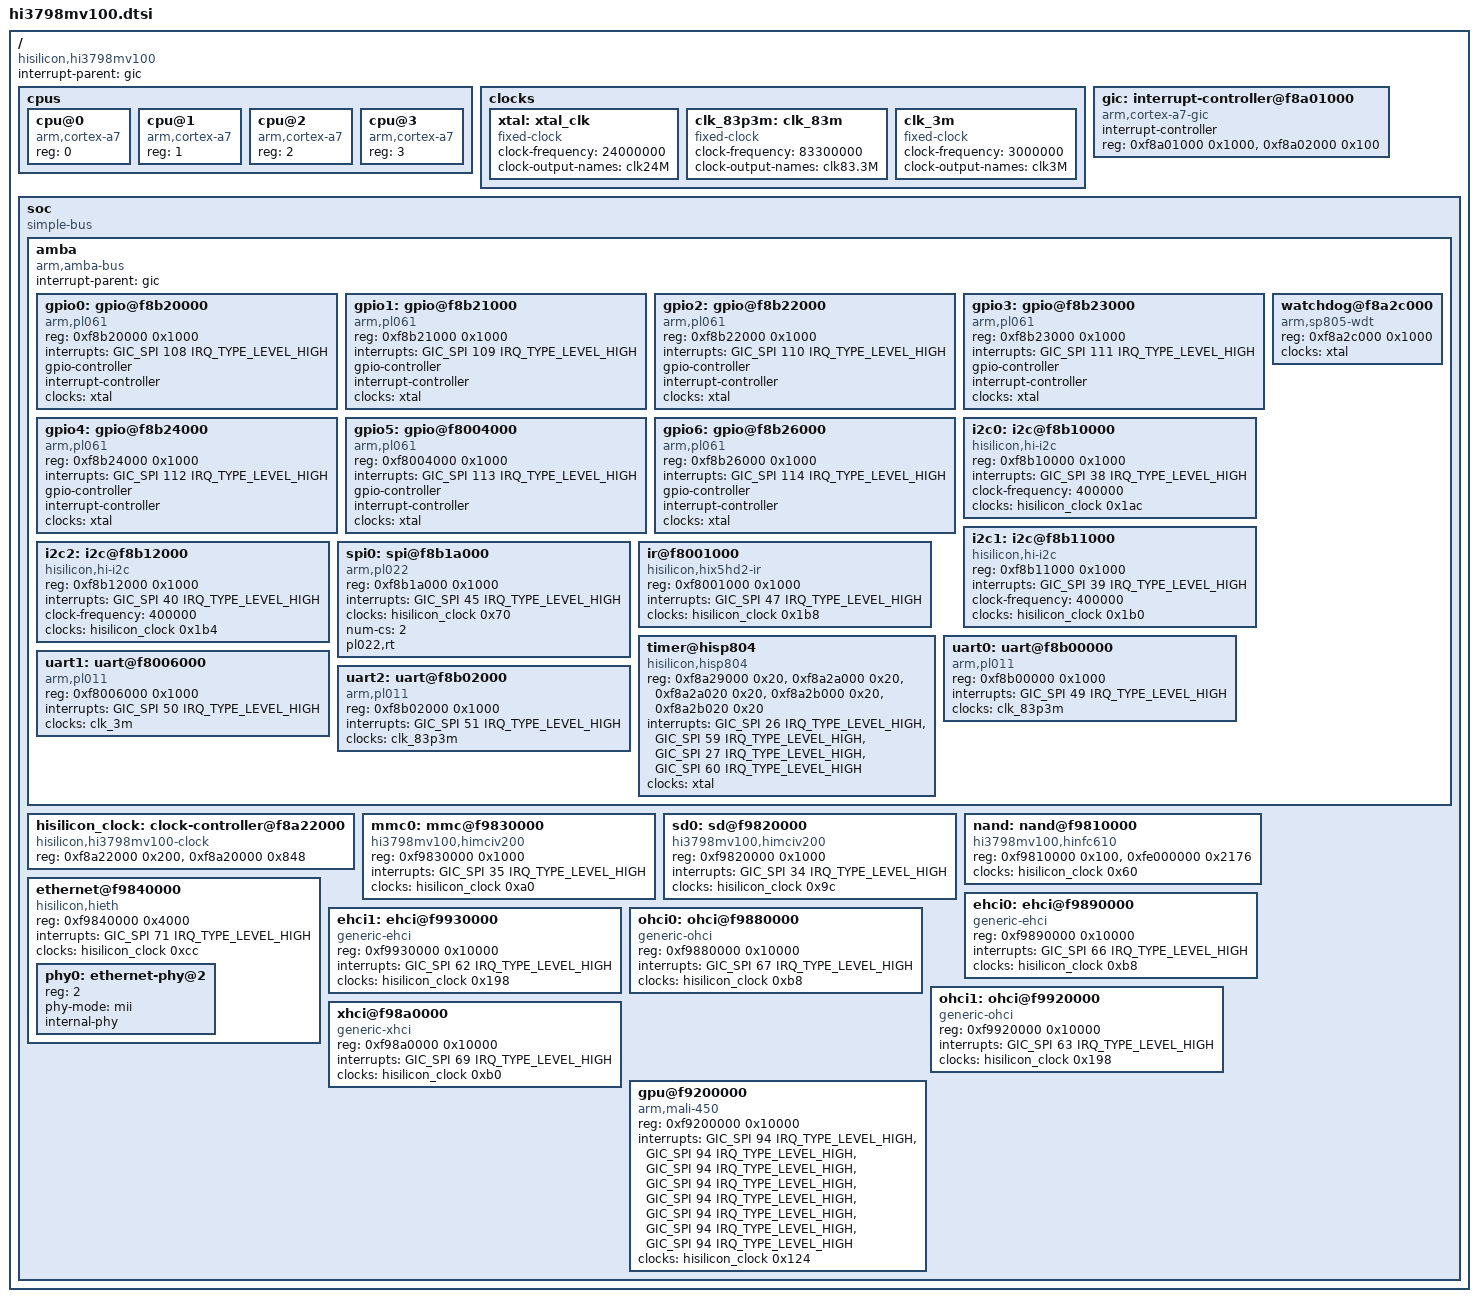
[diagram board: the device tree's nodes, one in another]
// SPDX-License-Identifier: GPL-2.0
/*
 * Device Tree Include for HiSilicon Hi3798MV100 SoC
 * Merged and cleaned from vendor dump + mainline-style structure
 */

#include <dt-bindings/interrupt-controller/arm-gic.h>
#include <dt-bindings/interrupt-controller/irq.h>

/ {
	compatible = "hisilicon,hi3798mv100";
	#address-cells = <1>;
	#size-cells = <1>;
	interrupt-parent = <&gic>;

	cpus {
		#address-cells = <1>;
		#size-cells = <0>;

		cpu@0 {
			device_type = "cpu";
			compatible = "arm,cortex-a7";
			reg = <0>;
		};
		cpu@1 {
			device_type = "cpu";
			compatible = "arm,cortex-a7";
			reg = <1>;
		};
		cpu@2 {
			device_type = "cpu";
			compatible = "arm,cortex-a7";
			reg = <2>;
		};
		cpu@3 {
			device_type = "cpu";
			compatible = "arm,cortex-a7";
			reg = <3>;
		};
	};

	clocks {
		xtal: xtal_clk {
			compatible = "fixed-clock";
			#clock-cells = <0>;
			clock-frequency = <24000000>;
			clock-output-names = "clk24M";
		};

		clk_83p3m: clk_83m {
			compatible = "fixed-clock";
			#clock-cells = <0>;
			clock-frequency = <83300000>;
			clock-output-names = "clk83.3M";
		};

		clk_3m: clk_3m {
			compatible = "fixed-clock";
			#clock-cells = <0>;
			clock-frequency = <3000000>;
			clock-output-names = "clk3M";
		};
	};

	gic: interrupt-controller@f8a01000 {
		compatible = "arm,cortex-a7-gic";
		#interrupt-cells = <3>;
		interrupt-controller;
		reg = <0xf8a01000 0x1000>,
		      <0xf8a02000 0x100>;
	};

	soc {
		compatible = "simple-bus";
		#address-cells = <1>;
		#size-cells = <1>;
		ranges;

		amba {
			compatible = "arm,amba-bus";
			#address-cells = <1>;
			#size-cells = <1>;
			ranges;
			interrupt-parent = <&gic>;

			/* GPIO Controllers */
			gpio0: gpio@f8b20000 {
				compatible = "arm,pl061", "arm,primecell";
				reg = <0xf8b20000 0x1000>;
				interrupts = <GIC_SPI 108 IRQ_TYPE_LEVEL_HIGH>;
				gpio-controller;
				#gpio-cells = <2>;
				interrupt-controller;
				#interrupt-cells = <2>;
				clocks = <&xtal>;
				clock-names = "apb_pclk";
			};

			gpio1: gpio@f8b21000 {
				compatible = "arm,pl061", "arm,primecell";
				reg = <0xf8b21000 0x1000>;
				interrupts = <GIC_SPI 109 IRQ_TYPE_LEVEL_HIGH>;
				gpio-controller;
				#gpio-cells = <2>;
				interrupt-controller;
				#interrupt-cells = <2>;
				clocks = <&xtal>;
				clock-names = "apb_pclk";
			};

			gpio2: gpio@f8b22000 {
				compatible = "arm,pl061", "arm,primecell";
				reg = <0xf8b22000 0x1000>;
				interrupts = <GIC_SPI 110 IRQ_TYPE_LEVEL_HIGH>;
				gpio-controller;
				#gpio-cells = <2>;
				interrupt-controller;
				#interrupt-cells = <2>;
				clocks = <&xtal>;
				clock-names = "apb_pclk";
			};

			gpio3: gpio@f8b23000 {
				compatible = "arm,pl061", "arm,primecell";
				reg = <0xf8b23000 0x1000>;
				interrupts = <GIC_SPI 111 IRQ_TYPE_LEVEL_HIGH>;
				gpio-controller;
				#gpio-cells = <2>;
				interrupt-controller;
				#interrupt-cells = <2>;
				clocks = <&xtal>;
				clock-names = "apb_pclk";
			};

			gpio4: gpio@f8b24000 {
				compatible = "arm,pl061", "arm,primecell";
				reg = <0xf8b24000 0x1000>;
				interrupts = <GIC_SPI 112 IRQ_TYPE_LEVEL_HIGH>;
				gpio-controller;
				#gpio-cells = <2>;
				interrupt-controller;
				#interrupt-cells = <2>;
				clocks = <&xtal>;
				clock-names = "apb_pclk";
			};

			gpio5: gpio@f8004000 {
				compatible = "arm,pl061", "arm,primecell";
				reg = <0xf8004000 0x1000>;
				interrupts = <GIC_SPI 113 IRQ_TYPE_LEVEL_HIGH>;
				gpio-controller;
				#gpio-cells = <2>;
				interrupt-controller;
				#interrupt-cells = <2>;
				clocks = <&xtal>;
				clock-names = "apb_pclk";
			};

			gpio6: gpio@f8b26000 {
				compatible = "arm,pl061", "arm,primecell";
				reg = <0xf8b26000 0x1000>;
				interrupts = <GIC_SPI 114 IRQ_TYPE_LEVEL_HIGH>;
				gpio-controller;
				#gpio-cells = <2>;
				interrupt-controller;
				#interrupt-cells = <2>;
				clocks = <&xtal>;
				clock-names = "apb_pclk";
			};

			/* Watchdog */
			watchdog@f8a2c000 {
				compatible = "arm,sp805-wdt", "arm,primecell";
				reg = <0xf8a2c000 0x1000>;
				clocks = <&xtal>;
				clock-names = "apb_pclk";
			};

			/* I2C */
			i2c0: i2c@f8b10000 {
				compatible = "hisilicon,hi-i2c";
				reg = <0xf8b10000 0x1000>;
				interrupts = <GIC_SPI 38 IRQ_TYPE_LEVEL_HIGH>;
				clock-frequency = <400000>;
				clocks = <&hisilicon_clock 0x1ac>; /* Adjust index if needed */
				#address-cells = <1>;
				#size-cells = <0>;
				status = "okay";
			};

			i2c1: i2c@f8b11000 {
				compatible = "hisilicon,hi-i2c";
				reg = <0xf8b11000 0x1000>;
				interrupts = <GIC_SPI 39 IRQ_TYPE_LEVEL_HIGH>;
				clock-frequency = <400000>;
				clocks = <&hisilicon_clock 0x1b0>;
				#address-cells = <1>;
				#size-cells = <0>;
			};

			i2c2: i2c@f8b12000 {
				compatible = "hisilicon,hi-i2c";
				reg = <0xf8b12000 0x1000>;
				interrupts = <GIC_SPI 40 IRQ_TYPE_LEVEL_HIGH>;
				clock-frequency = <400000>;
				clocks = <&hisilicon_clock 0x1b4>;
				#address-cells = <1>;
				#size-cells = <0>;
			};

			/* SPI */
			spi0: spi@f8b1a000 {
				compatible = "arm,pl022", "arm,primecell";
				reg = <0xf8b1a000 0x1000>;
				interrupts = <GIC_SPI 45 IRQ_TYPE_LEVEL_HIGH>;
				clocks = <&hisilicon_clock 0x70>;
				#address-cells = <1>;
				#size-cells = <0>;
				num-cs = <2>;
				pl022,rt;
			};

			/* IR */
			ir@f8001000 {
				compatible = "hisilicon,hix5hd2-ir";
				reg = <0xf8001000 0x1000>;
				interrupts = <GIC_SPI 47 IRQ_TYPE_LEVEL_HIGH>;
				clocks = <&hisilicon_clock 0x1b8>;
			};

			/* Timers */
			timer@hisp804 {
				compatible = "hisilicon,hisp804";
				reg = <0xf8a29000 0x20>,
				      <0xf8a2a000 0x20>,
				      <0xf8a2a020 0x20>,
				      <0xf8a2b000 0x20>,
				      <0xf8a2b020 0x20>;
				interrupts = <GIC_SPI 26 IRQ_TYPE_LEVEL_HIGH>,
					     <GIC_SPI 59 IRQ_TYPE_LEVEL_HIGH>,
					     <GIC_SPI 27 IRQ_TYPE_LEVEL_HIGH>,
					     <GIC_SPI 60 IRQ_TYPE_LEVEL_HIGH>;
				clocks = <&xtal>;
			};

			/* UARTs */
			uart0: uart@f8b00000 {
				compatible = "arm,pl011", "arm,primecell";
				reg = <0xf8b00000 0x1000>;
				interrupts = <GIC_SPI 49 IRQ_TYPE_LEVEL_HIGH>;
				clocks = <&clk_83p3m>;
				clock-names = "apb_pclk";
				status = "okay";
			};

			uart1: uart@f8006000 {
				compatible = "arm,pl011", "arm,primecell";
				reg = <0xf8006000 0x1000>;
				interrupts = <GIC_SPI 50 IRQ_TYPE_LEVEL_HIGH>;
				clocks = <&clk_3m>;
				clock-names = "apb_pclk";
			};

			uart2: uart@f8b02000 {
				compatible = "arm,pl011", "arm,primecell";
				reg = <0xf8b02000 0x1000>;
				interrupts = <GIC_SPI 51 IRQ_TYPE_LEVEL_HIGH>;
				clocks = <&clk_83p3m>;
				clock-names = "apb_pclk";
			};
		};

		/* Clock Controller */
		hisilicon_clock: clock-controller@f8a22000 {
			compatible = "hisilicon,hi3798mv100-clock";
			reg = <0xf8a22000 0x200>,
			      <0xf8a20000 0x848>;
			#clock-cells = <1>;
		};

		/* Storage */
		mmc0: mmc@f9830000 {
			compatible = "hi3798mv100,himciv200";
			reg = <0xf9830000 0x1000>;
			interrupts = <GIC_SPI 35 IRQ_TYPE_LEVEL_HIGH>;
			clocks = <&hisilicon_clock 0xa0>;
			clock-names = "clk";
			status = "okay";
		};

		sd0: sd@f9820000 {
			compatible = "hi3798mv100,himciv200";
			reg = <0xf9820000 0x1000>;
			interrupts = <GIC_SPI 34 IRQ_TYPE_LEVEL_HIGH>;
			clocks = <&hisilicon_clock 0x9c>;
			clock-names = "clk";
			status = "okay";
		};

		nand: nand@f9810000 {
			compatible = "hi3798mv100,hinfc610";
			reg = <0xf9810000 0x100>, <0xfe000000 0x2176>;
			clocks = <&hisilicon_clock 0x60>;
			clock-names = "clk";
		};

		/* Networking */
		ethernet@f9840000 {
			compatible = "hisilicon,hieth";
			reg = <0xf9840000 0x4000>;
			interrupts = <GIC_SPI 71 IRQ_TYPE_LEVEL_HIGH>;
			clocks = <&hisilicon_clock 0xcc>;
			clock-names = "clk";
			#address-cells = <1>;
			#size-cells = <0>;

			phy0: ethernet-phy@2 {
				reg = <2>;
				phy-mode = "mii";
				internal-phy;
			};
		};

		/* USB */
		ehci0: ehci@f9890000 {
			compatible = "generic-ehci";
			reg = <0xf9890000 0x10000>;
			interrupts = <GIC_SPI 66 IRQ_TYPE_LEVEL_HIGH>;
			clocks = <&hisilicon_clock 0xb8>;
			clock-names = "clk";
			status = "okay";
		};

		ehci1: ehci@f9930000 {
			compatible = "generic-ehci";
			reg = <0xf9930000 0x10000>;
			interrupts = <GIC_SPI 62 IRQ_TYPE_LEVEL_HIGH>;
			clocks = <&hisilicon_clock 0x198>;
			clock-names = "clk";
		};

		ohci0: ohci@f9880000 {
			compatible = "generic-ohci";
			reg = <0xf9880000 0x10000>;
			interrupts = <GIC_SPI 67 IRQ_TYPE_LEVEL_HIGH>;
			clocks = <&hisilicon_clock 0xb8>;
			clock-names = "clk";
		};

		ohci1: ohci@f9920000 {
			compatible = "generic-ohci";
			reg = <0xf9920000 0x10000>;
			interrupts = <GIC_SPI 63 IRQ_TYPE_LEVEL_HIGH>;
			clocks = <&hisilicon_clock 0x198>;
			clock-names = "clk";
		};

		xhci@f98a0000 {
			compatible = "generic-xhci";
			reg = <0xf98a0000 0x10000>;
			interrupts = <GIC_SPI 69 IRQ_TYPE_LEVEL_HIGH>;
			clocks = <&hisilicon_clock 0xb0>;
			clock-names = "clk";
			status = "okay";
		};

		/* GPU */
		gpu@f9200000 {
			compatible = "arm,mali-450", "arm,mali-utgard";
			reg = <0xf9200000 0x10000>;
			interrupts = <GIC_SPI 94 IRQ_TYPE_LEVEL_HIGH>, /* and others */
				     <GIC_SPI 94 IRQ_TYPE_LEVEL_HIGH>,
				     <GIC_SPI 94 IRQ_TYPE_LEVEL_HIGH>,
				     <GIC_SPI 94 IRQ_TYPE_LEVEL_HIGH>,
				     <GIC_SPI 94 IRQ_TYPE_LEVEL_HIGH>,
				     <GIC_SPI 94 IRQ_TYPE_LEVEL_HIGH>,
				     <GIC_SPI 94 IRQ_TYPE_LEVEL_HIGH>,
				     <GIC_SPI 94 IRQ_TYPE_LEVEL_HIGH>;
			interrupt-names = "IRQGP", "IRQGPMMU", "IRQPP0", "IRQPPMMU0",
					  "IRQPP1", "IRQPPMMU1", "IRQPMU", "IRQPP";
			clocks = <&hisilicon_clock 0x124>;
			clock-names = "clk_mali";
			status = "okay";
		};

		/* Add more nodes (regulator, virtdev, etc.) as needed */
	};
};
